AUTOSAR XML (schema 4-3-0)
package /SeatHeater
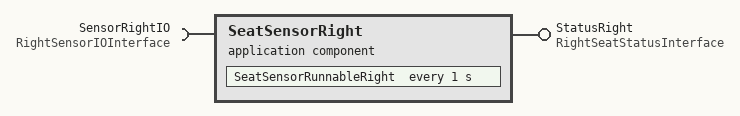
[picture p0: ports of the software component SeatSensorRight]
  application sw component type SeatSensorRight
    provide port StatusRight: nonqueued-sender-com-spec=PassengerOnRightSeat, provided-interface=RightSeatStatusInterface
    require port SensorRightIO: nonqueued-receiver-com-spec=RightSensorValue, required-interface=RightSensorIOInterface
    behavior SeatSensorRight_InternalBehavior
      events:
        timing event SeatSensorRightUpdateTimer: start-on-event=SeatSensorRunnableRight, period=1
      runnable SeatSensorRunnableRight
        data-send-points:
          access SeatSensorRightStatusAccess: accessed-variable=StatusRight.PassengerOnRightSeat
        data-receive-point-by-values:
          access SeatSensorRightIOAccess: accessed-variable=SensorRightIO.RightSensorValue
  swc implementation SeatSensorRight_Implementation: behavior=SeatSensorRight_InternalBehavior
